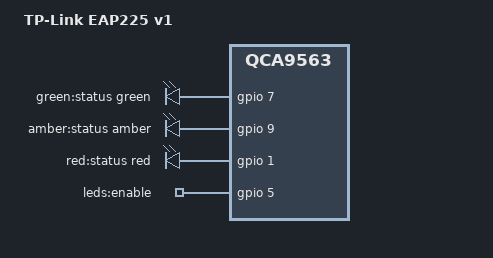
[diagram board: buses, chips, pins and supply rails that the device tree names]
// SPDX-License-Identifier: GPL-2.0-or-later OR MIT

#include <dt-bindings/leds/common.h>
#include "qca9563_tplink_eap2x5-1port.dtsi"

/ {
	compatible = "tplink,eap225-v1", "qca,qca9563";
	model = "TP-Link EAP225 v1";

	aliases {
		led-boot = &led_status_green;
		led-failsafe = &led_status_amber;
		led-running = &led_status_green;
		led-upgrade = &led_status_amber;
	};

	leds {
		compatible = "gpio-leds";

		led_status_green: led-0 {
			label = "green:status";
			color = <LED_COLOR_ID_GREEN>;
			function = LED_FUNCTION_STATUS;
			gpios = <&gpio 7 GPIO_ACTIVE_HIGH>;
			default-state = "on";
		};

		led_status_amber: led-1 {
			label = "amber:status";
			color = <LED_COLOR_ID_AMBER>;
			function = LED_FUNCTION_STATUS;
			gpios = <&gpio 9 GPIO_ACTIVE_HIGH>;
		};

		led_status_red: led-2 {
			label = "red:status";
			color = <LED_COLOR_ID_RED>;
			function = LED_FUNCTION_STATUS;
			gpios = <&gpio 1 GPIO_ACTIVE_HIGH>;
		};
	};

	gpio-export {
		compatible = "gpio-export";
		led_enable {
			gpio-export,name = "leds:enable";
			gpio-export,output = <1>;
			gpios = <&gpio 5 GPIO_ACTIVE_HIGH>;
		};
	};
};
